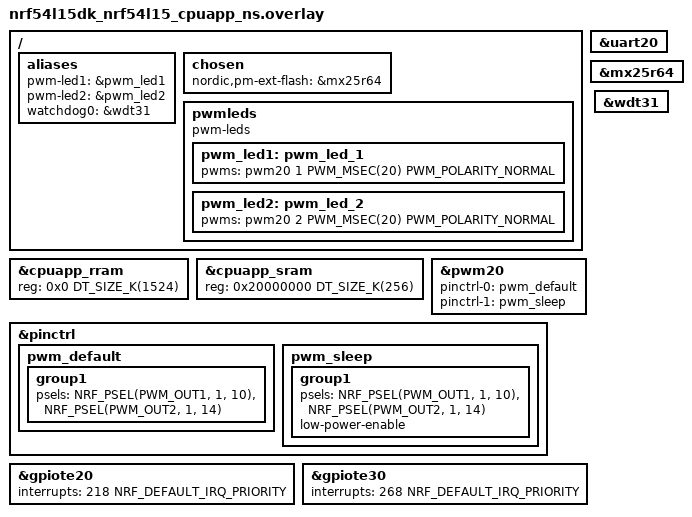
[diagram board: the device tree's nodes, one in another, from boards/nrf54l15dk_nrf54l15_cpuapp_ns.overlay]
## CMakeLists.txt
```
#
# Copyright (c) 2022 Nordic Semiconductor ASA
#
# SPDX-License-Identifier: LicenseRef-Nordic-5-Clause
#

cmake_minimum_required(VERSION 3.20.0)

find_package(Zephyr HINTS $ENV{ZEPHYR_BASE})

project(matter-window-app)

# Enable GNU STD support.
include(${ZEPHYR_CONNECTEDHOMEIP_MODULE_DIR}/config/nrfconnect/app/enable-gnu-std.cmake)

# NORDIC SDK APP START

# Include all source files that are located in the Matter common directory.
include(${ZEPHYR_NRF_MODULE_DIR}/samples/matter/common/cmake/source_common.cmake)

# Include Data Model utils
include(${ZEPHYR_NRF_MODULE_DIR}/samples/matter/common/cmake/data_model.cmake)

include(${ZEPHYR_NRF_MODULE_DIR}/samples/matter/common/cmake/zap_helpers.cmake)
ncs_get_zap_parent_dir(ZAP_PARENT_DIR)

target_include_directories(app PRIVATE
  src
  ${ZAP_PARENT_DIR}
)

target_sources(app PRIVATE
  src/app_task.cpp
  src/window_covering.cpp
  src/main.cpp
  src/zcl_callbacks.cpp
)

ncs_configure_data_model()
# NORDIC SDK APP END
```

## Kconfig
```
#
# Copyright (c) 2022 Nordic Semiconductor ASA
#
# SPDX-License-Identifier: LicenseRef-Nordic-5-Clause
#

mainmenu "Matter nRF Connect Window Covering Example Application"

config STATE_LEDS
	bool "Use LEDs to indicate the device state"
	default y
	help
	  Use LEDs to render the current state of the device such as the progress of commissioning of
	  the device into a network or the factory reset initiation. Note that setting this option to
	  'n' does not disable the LED indicating the state of the simulated bolt.

# Reduce Thread TX output power to 0 dBm for SED device
config OPENTHREAD_DEFAULT_TX_POWER
	default 0

source "$(ZEPHYR_CONNECTEDHOMEIP_MODULE_DIR)/config/nrfconnect/chip-module/Kconfig.features"
source "$(ZEPHYR_CONNECTEDHOMEIP_MODULE_DIR)/config/nrfconnect/chip-module/Kconfig.defaults"
source "$(ZEPHYR_NRF_MODULE_DIR)/samples/matter/common/src/Kconfig"
source "Kconfig.zephyr"
```

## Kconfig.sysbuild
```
#
# Copyright (c) 2023 Nordic Semiconductor ASA
#
# SPDX-License-Identifier: LicenseRef-Nordic-5-Clause
#

#### Radio core selection
config NRF_DEFAULT_IPC_RADIO
	default y

# Enable IEEE802.15.4 serialization to network core
# This config automatically pulls in the `overlay-802154.conf` in the ipc_radio image
config NETCORE_IPC_RADIO_IEEE802154
	default y if SOC_SERIES_NRF53X

# Enable Bluetooth serialization to network core
# This config automatically pulls in the `overlay-bt_hci_ipc.conf` in the ipc_radio image
config NETCORE_IPC_RADIO_BT_HCI_IPC
	default y if SOC_SERIES_NRF53X

#### Bootloader
choice BOOTLOADER
	default BOOTLOADER_MCUBOOT if !BOARD_NRF21540DK
endchoice

if BOOTLOADER_MCUBOOT

#### DFU multi-image support
config DFU_MULTI_IMAGE_PACKAGE_BUILD
	default y

config DFU_MULTI_IMAGE_PACKAGE_APP
	default y

config PM_EXTERNAL_FLASH_MCUBOOT_SECONDARY
	default y

#### DFU network core configuration
if SOC_SERIES_NRF53X

choice MCUBOOT_MODE
	default MCUBOOT_MODE_OVERWRITE_ONLY
endchoice

choice BOOT_SIGNATURE_TYPE
	default BOOT_SIGNATURE_TYPE_RSA
endchoice

config SECURE_BOOT_NETCORE
	default y

config NETCORE_APP_UPDATE
	default y

config DFU_MULTI_IMAGE_PACKAGE_NET
	default y

endif # SOC_SERIES_NRF53X

if BOARD_NRF54L15DK || BOARD_NRF54LM20DK || BOARD_XIAO_NRF54LM20A

# Disable checking the external drivers for nRF54L15 and nRF54LM20 DKs.
config PM_OVERRIDE_EXTERNAL_DRIVER_CHECK
	default y

endif # BOARD_NRF54L15DK || BOARD_NRF54LM20DK || BOARD_XIAO_NRF54LM20A

endif # BOOTLOADER_MCUBOOT

#### Enable generating factory data
config MATTER_FACTORY_DATA_GENERATE
	default y if !BOARD_NRF21540DK && !BOARD_XIAO_NRF54LM20A

source "share/sysbuild/Kconfig"
```

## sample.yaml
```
sample:
  description: Matter Window Covering example
  name: Matter Window Covering
common:
  tags:
    - sysbuild
    - ci_samples_matter
tests:
  sample.matter.window_cover.debug:
    sysbuild: true
    build_only: true
    integration_platforms:
      - nrf52840dk/nrf52840
      - nrf5340dk/nrf5340/cpuapp
      - nrf54l15dk/nrf54l15/cpuapp
      - nrf54l15dk/nrf54l15/cpuapp/ns
      - nrf54lm20dk/nrf54lm20a/cpuapp
    platform_allow:
      - nrf52840dk/nrf52840
      - nrf5340dk/nrf5340/cpuapp
      - nrf54l15dk/nrf54l15/cpuapp
      - nrf54l15dk/nrf54l15/cpuapp/ns
      - nrf54lm20dk/nrf54lm20a/cpuapp
  sample.matter.window_cover.release:
    sysbuild: true
    build_only: true
    extra_args:
      - FILE_SUFFIX=release
      - SB_CONFIG_BOOTLOADER_MCUBOOT=y
      - SB_CONFIG_PARTITION_MANAGER=y
    integration_platforms:
      - nrf52840dk/nrf52840
      - nrf5340dk/nrf5340/cpuapp
      - nrf54l15dk/nrf54l15/cpuapp
      - nrf54lm20dk/nrf54lm20a/cpuapp
    platform_allow:
      - nrf52840dk/nrf52840
      - nrf5340dk/nrf5340/cpuapp
      - nrf54l15dk/nrf54l15/cpuapp
      - nrf54lm20dk/nrf54lm20a/cpuapp
  sample.matter.window_cover.release.power_consumption:
    sysbuild: true
    build_only: true
    extra_args:
      - FILE_SUFFIX=release
      - CONFIG_NCS_SAMPLE_MATTER_LEDS=n
      - CONFIG_NCS_SAMPLE_MATTER_WATCHDOG=n
      - CONFIG_CHIP_ENABLE_PAIRING_AUTOSTART=y
    integration_platforms:
      - nrf52840dk/nrf52840
      - nrf5340dk/nrf5340/cpuapp
      - nrf54l15dk/nrf54l15/cpuapp
      - nrf54lm20dk/nrf54lm20a/cpuapp
    platform_allow:
      - nrf52840dk/nrf52840
      - nrf5340dk/nrf5340/cpuapp
      - nrf54l15dk/nrf54l15/cpuapp
      - nrf54lm20dk/nrf54lm20a/cpuapp
```

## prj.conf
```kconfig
#
# Copyright (c) 2022 Nordic Semiconductor ASA
#
# SPDX-License-Identifier: LicenseRef-Nordic-5-Clause
#

# This sample uses Kconfig.defaults to set options common for all
# samples. This file should contain only options specific for this sample
# or overrides of default values.

# Enable CHIP
CONFIG_CHIP=y
CONFIG_CHIP_PROJECT_CONFIG="src/chip_project_config.h"
CONFIG_CHIP_DEVICE_PRODUCT_NAME="Matter Window Covering"

# Configure ZAP file name
CONFIG_NCS_SAMPLE_MATTER_ZAP_FILE_PATH="${APPLICATION_CONFIG_DIR}/src/default_zap/window-app.zap"

# 32784 == 0x8010 (example window-app)
CONFIG_CHIP_DEVICE_PRODUCT_ID=32784
CONFIG_STD_CPP17=y

# Enable Matter pairing automatically on application start.
CONFIG_CHIP_ENABLE_PAIRING_AUTOSTART=y

# Enable Matter extended announcement and increase duration to 1 hour.
CONFIG_CHIP_BLE_EXT_ADVERTISING=y
CONFIG_CHIP_BLE_ADVERTISING_DURATION=60

# Add support for LEDs and buttons on Nordic development kits
CONFIG_DK_LIBRARY=y

# PWM support
CONFIG_PWM=y

# OpenThread configs
CONFIG_OPENTHREAD_NORDIC_LIBRARY_MTD=y
CONFIG_OPENTHREAD_MTD=y
CONFIG_OPENTHREAD_FTD=n
CONFIG_CHIP_ENABLE_ICD_SUPPORT=y
CONFIG_CHIP_THREAD_SSED=y
CONFIG_CHIP_ICD_SLOW_POLL_INTERVAL=500
CONFIG_CHIP_ICD_FAST_POLLING_INTERVAL=500

# Bluetooth Low Energy configuration
CONFIG_BT_DEVICE_NAME="MatterWinCov"

# Suspend devices when the CPU goes into sleep
CONFIG_PM_DEVICE=y

# Stack size settings
CONFIG_IEEE802154_NRF5_RX_STACK_SIZE=1024

# Other settings
CONFIG_THREAD_NAME=y
CONFIG_MPU_STACK_GUARD=y
CONFIG_RESET_ON_FATAL_ERROR=n
CONFIG_CHIP_LIB_SHELL=y
CONFIG_NCS_SAMPLE_MATTER_TEST_SHELL=y

# Reduce application size
CONFIG_USE_SEGGER_RTT=n

# Enable Factory Data feature
CONFIG_CHIP_FACTORY_DATA=y
CONFIG_CHIP_FACTORY_DATA_BUILD=y
```

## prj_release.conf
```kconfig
#
# Copyright (c) 2022 Nordic Semiconductor ASA
#
# SPDX-License-Identifier: LicenseRef-Nordic-5-Clause
#

# This sample uses Kconfig.defaults to set options common for all
# samples. This file should contain only options specific for this sample
# or overrides of default values.

# Enable CHIP
CONFIG_CHIP=y
CONFIG_CHIP_PROJECT_CONFIG="src/chip_project_config.h"
CONFIG_CHIP_DEVICE_PRODUCT_NAME="Matter Window Covering"

# Configure ZAP file name
CONFIG_NCS_SAMPLE_MATTER_ZAP_FILE_PATH="${APPLICATION_CONFIG_DIR}/src/default_zap/window-app.zap"

# 32784 == 0x8010 (example window-app)
CONFIG_CHIP_DEVICE_PRODUCT_ID=32784
CONFIG_STD_CPP17=y

# Enable Matter pairing automatically on application start.
CONFIG_CHIP_ENABLE_PAIRING_AUTOSTART=y

# Enable Matter extended announcement and increase duration to 1 hour.
CONFIG_CHIP_BLE_EXT_ADVERTISING=y
CONFIG_CHIP_BLE_ADVERTISING_DURATION=60

# Add support for LEDs and buttons on Nordic development kits
CONFIG_DK_LIBRARY=y

# Try to disable unused RAM blocks to reduce power consumption
CONFIG_RAM_POWER_DOWN_LIBRARY=y

# PWM support
CONFIG_PWM=y

# OpenThread configs
CONFIG_OPENTHREAD_NORDIC_LIBRARY_MTD=y
CONFIG_OPENTHREAD_MTD=y
CONFIG_OPENTHREAD_FTD=n
CONFIG_CHIP_ENABLE_ICD_SUPPORT=y
CONFIG_CHIP_THREAD_SSED=y
CONFIG_CHIP_ICD_SLOW_POLL_INTERVAL=500
CONFIG_CHIP_ICD_FAST_POLLING_INTERVAL=500

# Bluetooth Low Energy configuration
CONFIG_BT_DEVICE_NAME="MatterWinCov"

# Suspend devices when the CPU goes into sleep
CONFIG_PM_DEVICE=y

# Stack size settings
CONFIG_IEEE802154_NRF5_RX_STACK_SIZE=1024

# Enable system reset on fatal error
CONFIG_RESET_ON_FATAL_ERROR=y

# Disable all debug features
CONFIG_USE_SEGGER_RTT=n
CONFIG_SHELL=n
CONFIG_OPENTHREAD_SHELL=n
CONFIG_CONSOLE=n
CONFIG_UART_CONSOLE=n
CONFIG_SERIAL=n
CONFIG_LOG=n
CONFIG_LOG_MODE_MINIMAL=n
CONFIG_ASSERT_VERBOSE=n
CONFIG_ASSERT_NO_FILE_INFO=y
CONFIG_PRINTK=n
CONFIG_PRINTK_SYNC=n
CONFIG_THREAD_NAME=n
CONFIG_BOOT_BANNER=n

# Enable Factory Data feature
CONFIG_CHIP_FACTORY_DATA=y
CONFIG_CHIP_FACTORY_DATA_BUILD=y

# Enable Watchdog
CONFIG_NCS_SAMPLE_MATTER_WATCHDOG=y

# Enable LTO to decrease the flash usage.
CONFIG_LTO=y
CONFIG_ISR_TABLES_LOCAL_DECLARATION=y
```

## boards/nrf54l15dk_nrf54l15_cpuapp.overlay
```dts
/*
 * Copyright (c) 2024 Nordic Semiconductor ASA
 *
 * SPDX-License-Identifier: LicenseRef-Nordic-5-Clause
 */

/ {
	chosen {
		nordic,pm-ext-flash = &mx25r64;
	};

	aliases {
		/* Configure PWM module for led1 (LED2 on the board) */
		pwm-led1 = &pwm_led1;
		pwm-led2 = &pwm_led2;

		/* Use watchdog wdt31 as the application watchdog */
		watchdog0 = &wdt31;
	};

	pwmleds {
		compatible = "pwm-leds";
		pwm_led1: pwm_led_1 {
			pwms = <&pwm20 1 PWM_MSEC(20) PWM_POLARITY_NORMAL>;
		};
		pwm_led2: pwm_led_2 {
			pwms = <&pwm20 2 PWM_MSEC(20) PWM_POLARITY_NORMAL>;
		};
	};
};

/* restore full RRAM and SRAM space - by default some parts are dedicated to FLRP */
&cpuapp_rram {
	reg = <0x0 DT_SIZE_K(1524)>;
};

&cpuapp_sram {
	reg = <0x20000000 DT_SIZE_K(256)>;
	ranges = <0x0 0x20000000  0x40000>;
};

/* TODO: re-enable HWFC once it's fixed */
&uart20 {
	/delete-property/ hw-flow-control;
};

&mx25r64 {
	status = "okay";
};

&pwm20 {
	status = "okay";
	pinctrl-0 = <&pwm_default>;
	pinctrl-1 = <&pwm_sleep>;
	pinctrl-names = "default", "sleep";
};

&pinctrl {
	pwm_default: pwm_default {
		group1 {
			psels = <NRF_PSEL(PWM_OUT1, 1, 10)>, <NRF_PSEL(PWM_OUT2, 1, 14)>;
		};
	};
	pwm_sleep: pwm_sleep {
		group1 {
			psels = <NRF_PSEL(PWM_OUT1, 1, 10)>, <NRF_PSEL(PWM_OUT2, 1, 14)>;
			low-power-enable;
		};
	};
};

&wdt31 {
	status = "okay";
};
```

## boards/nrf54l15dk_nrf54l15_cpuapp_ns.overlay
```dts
/*
 * Copyright (c) 2024 Nordic Semiconductor ASA
 *
 * SPDX-License-Identifier: LicenseRef-Nordic-5-Clause
 */

/ {
	aliases {
		/* Configure PWM module for led1 (LED2 on the board) */
		pwm-led1 = &pwm_led1;
		pwm-led2 = &pwm_led2;

		/* Use watchdog wdt31 as the application watchdog */
		watchdog0 = &wdt31;
	};

	chosen {
		nordic,pm-ext-flash = &mx25r64;
	};

	pwmleds {
		compatible = "pwm-leds";
		pwm_led1: pwm_led_1 {
			pwms = <&pwm20 1 PWM_MSEC(20) PWM_POLARITY_NORMAL>;
		};
		pwm_led2: pwm_led_2 {
			pwms = <&pwm20 2 PWM_MSEC(20) PWM_POLARITY_NORMAL>;
		};
	};
};

/* restore full RRAM and SRAM space - by default some parts are dedicated to FLRP */
&cpuapp_rram {
	reg = <0x0 DT_SIZE_K(1524)>;
};

&cpuapp_sram {
	reg = <0x20000000 DT_SIZE_K(256)>;
	ranges = <0x0 0x20000000  0x40000>;
};

/* TODO: re-enable HWFC once it's fixed */
&uart20 {
	/delete-property/ hw-flow-control;
};

&mx25r64 {
	status = "okay";
};

&pwm20 {
	status = "okay";
	pinctrl-0 = <&pwm_default>;
	pinctrl-1 = <&pwm_sleep>;
	pinctrl-names = "default", "sleep";
};

&pinctrl {
	pwm_default: pwm_default {
		group1 {
			psels = <NRF_PSEL(PWM_OUT1, 1, 10)>, <NRF_PSEL(PWM_OUT2, 1, 14)>;
		};
	};
	pwm_sleep: pwm_sleep {
		group1 {
			psels = <NRF_PSEL(PWM_OUT1, 1, 10)>, <NRF_PSEL(PWM_OUT2, 1, 14)>;
			low-power-enable;
		};
	};
};

&wdt31 {
	status = "okay";
};

/* Change IRQ ids to handle button interrupts.
 * The default values for nRF54L15 are 219 and 269,
 * but with TF-M they are reserved for the secure domain
 * (218 and 268 are reserved for the non-secure domain).
 */
&gpiote20 {
	interrupts = <218 NRF_DEFAULT_IRQ_PRIORITY>;
};

&gpiote30 {
	interrupts = <268 NRF_DEFAULT_IRQ_PRIORITY>;
};
```

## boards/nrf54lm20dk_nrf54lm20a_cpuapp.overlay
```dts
/*
 * Copyright (c) 2025 Nordic Semiconductor ASA
 *
 * SPDX-License-Identifier: LicenseRef-Nordic-5-Clause
 */

/ {
	chosen {
		nordic,pm-ext-flash = &mx25r64;
	};

	aliases {
		pwm-led1 = &pwm_led1;
		pwm-led2 = &pwm_led2;

		/* Use watchdog wdt31 as the application watchdog */
		watchdog0 = &wdt31;
	};

	pwmleds {
		compatible = "pwm-leds";
		pwm_led1: pwm_led_1 {
			pwms = <&pwm20 1 PWM_MSEC(20) PWM_POLARITY_NORMAL>;
		};
		pwm_led2: pwm_led_2 {
			pwms = <&pwm20 2 PWM_MSEC(20) PWM_POLARITY_NORMAL>;
		};
	};
};

&pwm20 {
	status = "okay";
	pinctrl-0 = <&pwm_default>;
	pinctrl-1 = <&pwm_sleep>;
	pinctrl-names = "default", "sleep";
};

&pinctrl {
	pwm_default: pwm_default {
		group1 {
			psels = <NRF_PSEL(PWM_OUT1, 1, 25)>, <NRF_PSEL(PWM_OUT2, 1, 27)>;
		};
	};
	pwm_sleep: pwm_sleep {
		group1 {
			psels = <NRF_PSEL(PWM_OUT1, 1, 25)>, <NRF_PSEL(PWM_OUT2, 1, 27)>;
			low-power-enable;
		};
	};
};

&mx25r64 {
	status = "okay";
};

&wdt31 {
	status = "okay";
};
```

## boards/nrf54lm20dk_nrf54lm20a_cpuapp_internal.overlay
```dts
/*
 * Copyright (c) 2025 Nordic Semiconductor ASA
 *
 * SPDX-License-Identifier: LicenseRef-Nordic-5-Clause
 */

/ {
	aliases {
		/* Configure PWM module for led1 (LED2 on the board) */
		pwm-led1 = &pwm_led1;

		/* Use watchdog wdt31 as the application watchdog */
		watchdog0 = &wdt31;
	};

	pwmleds {
		compatible = "pwm-leds";
		pwm_led1: pwm_led_1 {
			pwms = <&pwm20 1 PWM_MSEC(20) PWM_POLARITY_NORMAL>;
		};
		pwm_led2: pwm_led_2 {
			pwms = <&pwm20 2 PWM_MSEC(20) PWM_POLARITY_NORMAL>;
		};
	};
};
&pwm20 {
	status = "okay";
	pinctrl-0 = <&pwm_default>;
	pinctrl-1 = <&pwm_sleep>;
	pinctrl-names = "default", "sleep";
};


&pinctrl {
	pwm_default: pwm_default {
		group1 {
			psels = <NRF_PSEL(PWM_OUT1, 1, 25)>, <NRF_PSEL(PWM_OUT2, 1, 27)>;
		};
	};
	pwm_sleep: pwm_sleep {
		group1 {
			psels = <NRF_PSEL(PWM_OUT1, 1, 25)>, <NRF_PSEL(PWM_OUT2, 1, 27)>;
			low-power-enable;
		};
	};
};

&mx25r64 {
	status = "disabled";
};

&wdt31 {
	status = "okay";
};
```

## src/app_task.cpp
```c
/*
 * Copyright (c) 2022 Nordic Semiconductor ASA
 *
 * SPDX-License-Identifier: LicenseRef-Nordic-5-Clause
 */

#include "app_task.h"

#include "window_covering.h"

#include "app/matter_init.h"
#include "app/task_executor.h"
#include "clusters/identify.h"

#include <setup_payload/OnboardingCodesUtil.h>

#include <zephyr/logging/log.h>

LOG_MODULE_DECLARE(app, CONFIG_CHIP_APP_LOG_LEVEL);

using namespace ::chip;
using namespace ::chip::app;
using namespace ::chip::DeviceLayer;

namespace
{
Nrf::Matter::IdentifyCluster sIdentifyCluster(WindowCovering::Endpoint());

#define OPEN_BUTTON_MASK DK_BTN2_MSK
#define CLOSE_BUTTON_MASK DK_BTN3_MSK
} /* namespace */

void AppTask::ButtonEventHandler(Nrf::ButtonState state, Nrf::ButtonMask hasChanged)
{
	if (OPEN_BUTTON_MASK & hasChanged) {
		WindowButtonAction action =
			(OPEN_BUTTON_MASK & state) ? WindowButtonAction::Pressed : WindowButtonAction::Released;
		Nrf::PostTask([action] { OpenHandler(action); });
	}

	if (CLOSE_BUTTON_MASK & hasChanged) {
		WindowButtonAction action =
			(CLOSE_BUTTON_MASK & state) ? WindowButtonAction::Pressed : WindowButtonAction::Released;
		Nrf::PostTask([action] { CloseHandler(action); });
	}
}

void AppTask::OpenHandler(const WindowButtonAction &action)
{
	if (action == WindowButtonAction::Pressed) {
		Instance().mOpenButtonIsPressed = true;
		if (Instance().mCloseButtonIsPressed) {
			Instance().ToggleMoveType();
		}
	} else {
		if (!Instance().mCloseButtonIsPressed) {
			if (!Instance().mMoveTypeRecentlyChanged) {
				WindowCovering::Instance().SetSingleStepTarget(OperationalState::MovingUpOrOpen);
			} else {
				Instance().mMoveTypeRecentlyChanged = false;
			}
		}
		Instance().mOpenButtonIsPressed = false;
	}
}

void AppTask::CloseHandler(const WindowButtonAction &action)
{
	if (action == WindowButtonAction::Pressed) {
		Instance().mCloseButtonIsPressed = true;
		if (Instance().mOpenButtonIsPressed) {
			Instance().ToggleMoveType();
		}
	} else {
		if (!Instance().mOpenButtonIsPressed) {
			if (!Instance().mMoveTypeRecentlyChanged) {
				WindowCovering::Instance().SetSingleStepTarget(OperationalState::MovingDownOrClose);
			} else {
				Instance().mMoveTypeRecentlyChanged = false;
			}
		}
		Instance().mCloseButtonIsPressed = false;
	}
}

void AppTask::ToggleMoveType()
{
	if (WindowCovering::Instance().GetMoveType() == WindowCovering::MoveType::LIFT) {
		WindowCovering::Instance().SetMoveType(WindowCovering::MoveType::TILT);
		LOG_INF("Window covering move: tilt");
	} else {
		WindowCovering::Instance().SetMoveType(WindowCovering::MoveType::LIFT);
		LOG_INF("Window covering move: lift");
	}
	mMoveTypeRecentlyChanged = true;
}

CHIP_ERROR AppTask::Init()
{
	/* Initialize Matter stack */
	ReturnErrorOnFailure(Nrf::Matter::PrepareServer(Nrf::Matter::InitData{ .mPostServerInitClbk = [] {
		WindowCovering::Instance().PositionLEDUpdate(WindowCovering::MoveType::LIFT);
		WindowCovering::Instance().PositionLEDUpdate(WindowCovering::MoveType::TILT);
		return CHIP_NO_ERROR;
	} }));

	if (!Nrf::GetBoard().Init(ButtonEventHandler)) {
		LOG_ERR("User interface initialization failed.");
		return CHIP_ERROR_INCORRECT_STATE;
	}

	/* Register Matter event handler that controls the connectivity status LED based on the captured Matter network
	 * state. */
	ReturnErrorOnFailure(Nrf::Matter::RegisterEventHandler(Nrf::Board::DefaultMatterEventHandler, 0));

	ReturnErrorOnFailure(sIdentifyCluster.Init());

	return Nrf::Matter::StartServer();
}

CHIP_ERROR AppTask::StartApp()
{
	ReturnErrorOnFailure(Init());

	while (true) {
		Nrf::DispatchNextTask();
	}

	return CHIP_NO_ERROR;
}
```

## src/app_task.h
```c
/*
 * Copyright (c) 2022 Nordic Semiconductor ASA
 *
 * SPDX-License-Identifier: LicenseRef-Nordic-5-Clause
 */

#pragma once

#include "window_covering.h"

#include "board/led_widget.h"

#include <platform/CHIPDeviceLayer.h>

struct Identify;

enum class WindowButtonAction : uint8_t { Pressed, Released };

class AppTask {
public:
	static AppTask &Instance()
	{
		static AppTask sAppTask;
		return sAppTask;
	};

	CHIP_ERROR StartApp();

private:
	CHIP_ERROR Init();
	void ToggleMoveType();

	static void OpenHandler(const WindowButtonAction &action);
	static void CloseHandler(const WindowButtonAction &action);

	static void ButtonEventHandler(Nrf::ButtonState state, Nrf::ButtonMask hasChanged);

	OperationalState mMoveType{ OperationalState::MovingUpOrOpen };
	bool mMovementTimerActive{ false };
	bool mOpenButtonIsPressed{ false };
	bool mCloseButtonIsPressed{ false };
	bool mMoveTypeRecentlyChanged{ false };
};
```
